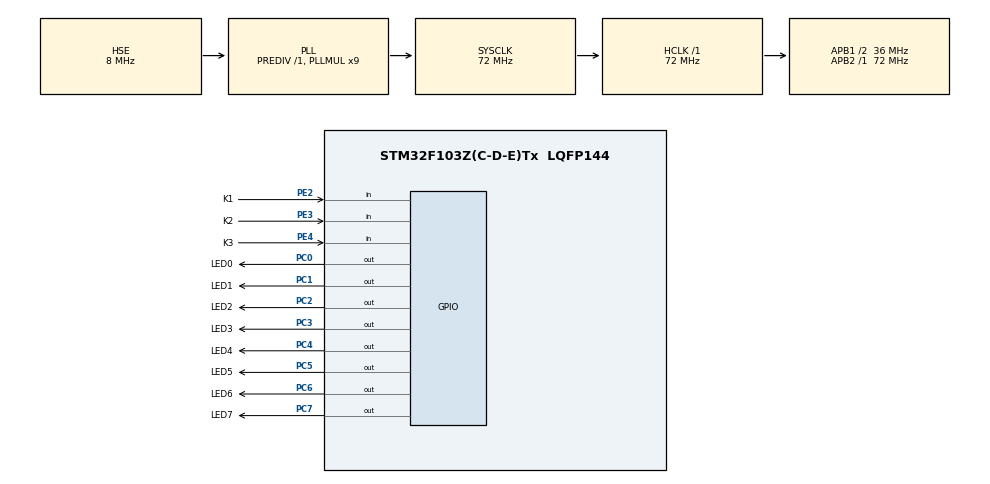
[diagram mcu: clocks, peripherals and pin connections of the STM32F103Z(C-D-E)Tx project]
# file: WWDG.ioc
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Mcu.Family=STM32F1
Mcu.Name=STM32F103Z(C-D-E)Tx
Mcu.Package=LQFP144
NVIC.PriorityGroup=NVIC_PRIORITYGROUP_4
NVIC.TIM2_IRQn=true\:0\:0\:false\:false\:true\:true\:true
NVIC.WWDG_IRQn=true\:0\:0\:false\:false\:true\:true\:true
OSC_IN.Mode=HSE-External-Oscillator
OSC_IN.Signal=RCC_OSC_IN
OSC_OUT.Mode=HSE-External-Oscillator
OSC_OUT.Signal=RCC_OSC_OUT
PA13.Mode=Serial_Wire
PA13.Signal=SYS_JTMS-SWDIO
PA14.Mode=Serial_Wire
PA14.Signal=SYS_JTCK-SWCLK
PC0.GPIO_Label=LED0
PC0.GPIO_ModeDefaultOutputPP=GPIO_MODE_OUTPUT_PP
PC0.GPIO_PuPd=GPIO_NOPULL
PC0.GPIO_Speed=GPIO_SPEED_FREQ_LOW
PC0.PinState=GPIO_PIN_SET
PC0.Signal=GPIO_Output
PC1.GPIO_Label=LED1
PC1.GPIO_ModeDefaultOutputPP=GPIO_MODE_OUTPUT_PP
PC1.GPIO_PuPd=GPIO_NOPULL
PC1.GPIO_Speed=GPIO_SPEED_FREQ_LOW
PC1.PinState=GPIO_PIN_SET
PC1.Signal=GPIO_Output
PC2.GPIO_Label=LED2
PC2.GPIO_ModeDefaultOutputPP=GPIO_MODE_OUTPUT_PP
PC2.GPIO_PuPd=GPIO_NOPULL
PC2.GPIO_Speed=GPIO_SPEED_FREQ_LOW
PC2.PinState=GPIO_PIN_SET
PC2.Signal=GPIO_Output
PC3.GPIO_Label=LED3
PC3.GPIO_ModeDefaultOutputPP=GPIO_MODE_OUTPUT_PP
PC3.GPIO_PuPd=GPIO_NOPULL
PC3.GPIO_Speed=GPIO_SPEED_FREQ_LOW
PC3.PinState=GPIO_PIN_SET
PC3.Signal=GPIO_Output
PC4.GPIO_Label=LED4
PC4.GPIO_ModeDefaultOutputPP=GPIO_MODE_OUTPUT_PP
PC4.GPIO_PuPd=GPIO_NOPULL
PC4.GPIO_Speed=GPIO_SPEED_FREQ_LOW
PC4.PinState=GPIO_PIN_SET
PC4.Signal=GPIO_Output
PC5.GPIO_Label=LED5
PC5.GPIO_ModeDefaultOutputPP=GPIO_MODE_OUTPUT_PP
PC5.GPIO_PuPd=GPIO_NOPULL
PC5.GPIO_Speed=GPIO_SPEED_FREQ_LOW
PC5.PinState=GPIO_PIN_SET
PC5.Signal=GPIO_Output
PC6.GPIO_Label=LED6
PC6.GPIO_ModeDefaultOutputPP=GPIO_MODE_OUTPUT_PP
PC6.GPIO_PuPd=GPIO_NOPULL
PC6.GPIO_Speed=GPIO_SPEED_FREQ_LOW
PC6.PinState=GPIO_PIN_SET
PC6.Signal=GPIO_Output
PC7.GPIO_Label=LED7
PC7.GPIO_ModeDefaultOutputPP=GPIO_MODE_OUTPUT_PP
PC7.GPIO_PuPd=GPIO_NOPULL
PC7.GPIO_Speed=GPIO_SPEED_FREQ_LOW
PC7.PinState=GPIO_PIN_SET
PC7.Signal=GPIO_Output
PE2.GPIO_Label=K1
PE2.GPIO_Mode=GPIO_MODE_INPUT
PE2.GPIO_PuPd=GPIO_NOPULL
PE2.Signal=GPIO_Input
PE3.GPIO_Label=K2
PE3.GPIO_Mode=GPIO_MODE_INPUT
PE3.GPIO_PuPd=GPIO_NOPULL
PE3.Signal=GPIO_Input
PE4.GPIO_Label=K3
PE4.GPIO_Mode=GPIO_MODE_INPUT
PE4.GPIO_PuPd=GPIO_NOPULL
PE4.Signal=GPIO_Input
ProjectManager.HeapSize=0x200
ProjectManager.StackSize=0x400
ProjectManager.TargetToolchain=MDK-ARM V5.27
RCC.AHBFreq_Value=72000000
RCC.APB1CLKDivider=RCC_HCLK_DIV2
RCC.APB1Freq_Value=36000000
RCC.APB1TimFreq_Value=72000000
RCC.APB2Freq_Value=72000000
RCC.APB2TimFreq_Value=72000000
RCC.HCLKFreq_Value=72000000
RCC.PLLMUL=RCC_PLL_MUL9
RCC.PLLSourceVirtual=RCC_PLLSOURCE_HSE
RCC.SYSCLKFreq_VALUE=72000000
RCC.SYSCLKSource=RCC_SYSCLKSOURCE_PLLCLK
RCC.USBFreq_Value=72000000
TIM2.AutoReloadPreload=TIM_AUTORELOAD_PRELOAD_ENABLE
TIM2.Period=10000-1
TIM2.Prescaler=72-1
VP_TIM2_VS_ClockSourceINT.Mode=Internal
VP_WWDG_VS_WWDG.Mode=WWDG_Activate
WWDG.Counter=127
WWDG.EWIMode=WWDG_EWI_ENABLE
WWDG.Prescaler=WWDG_PRESCALER_8
WWDG.Window=127
board=custom

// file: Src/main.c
/* USER CODE BEGIN Header */
/**
  ******************************************************************************
  * @file           : main.c
  * @brief          : Main program body
  ******************************************************************************
  * @attention
  *
  * <h2><center>&copy; Copyright (c) 2020 STMicroelectronics.
  * All rights reserved.</center></h2>
  *
  * This software component is licensed by ST under BSD 3-Clause license,
  * the "License"; You may not use this file except in compliance with the
  * License. You may obtain a copy of the License at:
  *                        opensource.org/licenses/BSD-3-Clause
  *
  ******************************************************************************
  */
/* USER CODE END Header */

#include "main.h"
#include "tim.h"
#include "wwdg.h"
#include "gpio.h"

void SystemClock_Config(void);

int main(void)
{

  /* MCU Configuration--------------------------------------------------------*/

  /* Reset of all peripherals, Initializes the Flash interface and the Systick. */
  HAL_Init();

  /* Configure the system clock */
  SystemClock_Config();

  /* Initialize all configured peripherals */
  MX_GPIO_Init();
  MX_TIM2_Init();
  MX_WWDG_Init();

  /* Infinite loop */
  while (1)
  {
		HAL_GPIO_TogglePin(LED7_GPIO_Port, LED7_Pin);
		HAL_Delay(500);
  }
}

void SystemClock_Config(void)
{
  RCC_OscInitTypeDef RCC_OscInitStruct = {0};
  RCC_ClkInitTypeDef RCC_ClkInitStruct = {0};

  /** Initializes the CPU, AHB and APB busses clocks
  */
  RCC_OscInitStruct.OscillatorType = RCC_OSCILLATORTYPE_HSE;
  RCC_OscInitStruct.HSEState = RCC_HSE_ON;
  RCC_OscInitStruct.HSEPredivValue = RCC_HSE_PREDIV_DIV1;
  RCC_OscInitStruct.HSIState = RCC_HSI_ON;
  RCC_OscInitStruct.PLL.PLLState = RCC_PLL_ON;
  RCC_OscInitStruct.PLL.PLLSource = RCC_PLLSOURCE_HSE;
  RCC_OscInitStruct.PLL.PLLMUL = RCC_PLL_MUL9;
  if (HAL_RCC_OscConfig(&RCC_OscInitStruct) != HAL_OK)
  {
    Error_Handler();
  }
  /** Initializes the CPU, AHB and APB busses clocks
  */
  RCC_ClkInitStruct.ClockType = RCC_CLOCKTYPE_HCLK|RCC_CLOCKTYPE_SYSCLK
                              |RCC_CLOCKTYPE_PCLK1|RCC_CLOCKTYPE_PCLK2;
  RCC_ClkInitStruct.SYSCLKSource = RCC_SYSCLKSOURCE_PLLCLK;
  RCC_ClkInitStruct.AHBCLKDivider = RCC_SYSCLK_DIV1;
  RCC_ClkInitStruct.APB1CLKDivider = RCC_HCLK_DIV2;
  RCC_ClkInitStruct.APB2CLKDivider = RCC_HCLK_DIV1;

  if (HAL_RCC_ClockConfig(&RCC_ClkInitStruct, FLASH_LATENCY_2) != HAL_OK)
  {
    Error_Handler();
  }
}

/* USER CODE BEGIN 4 */
void HAL_WWDG_EarlyWakeupCallback(WWDG_HandleTypeDef *hwwdg)
{
	HAL_WWDG_Refresh(hwwdg);
	static uint16_t i;
	if(++i == 10)
		i=0,HAL_GPIO_TogglePin(LED0_GPIO_Port, LED0_Pin);
}
/* USER CODE END 4 */

void Error_Handler(void)
{
}

/************************ (C) COPYRIGHT STMicroelectronics *****END OF FILE****/
